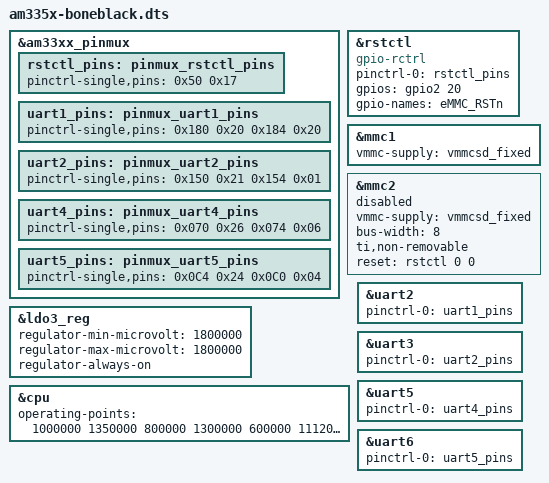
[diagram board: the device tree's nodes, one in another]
/*
 * Copyright (C) 2012 Texas Instruments Incorporated - http://www.ti.com/
 *
 * This program is free software; you can redistribute it and/or modify
 * it under the terms of the GNU General Public License version 2 as
 * published by the Free Software Foundation.
 */
/dts-v1/;

/include/ "am33xx.dtsi"

/include/ "am335x-bone-common.dtsi"

&am33xx_pinmux {
	rstctl_pins: pinmux_rstctl_pins {
		pinctrl-single,pins = <
			/* eMMC_RSTn */
			0x50 0x17	/* gpmc_a4.gpio1_20, OUTPUT | MODE7 | PULLUP */
		>;
	};

	uart1_pins: pinmux_uart1_pins {
		pinctrl-single,pins = <
			0x180 0x20	/* uart1_rxd.uart1_rxd */
			0x184 0x20	/* uart1_txd.uart1_txd */
		>;
	};

	uart2_pins: pinmux_uart2_pins {
		pinctrl-single,pins = <
			0x150 0x21	/* spi0_sclk.uart2_rxd | MODE1 */
			0x154 0x01	/* spi0_d0.uart2_txd | MODE1 */
		>;
	};

	uart4_pins: pinmux_uart4_pins {
		pinctrl-single,pins = <
			0x070 0x26	/* gpmc_wait0.uart4_rxd | MODE6 */
			0x074 0x06	/* gpmc_wpn.uart4_txd | MODE6 */
		>;
	};

	uart5_pins: pinmux_uart5_pins {
		pinctrl-single,pins = <
			0x0C4 0x24	/* lcd_data9.uart5_rxd | MODE4 */
			0x0C0 0x04	/* lcd_data8.uart5_txd | MODE4 */
		>;
	};
};

&ldo3_reg {
	regulator-min-microvolt = <1800000>;
	regulator-max-microvolt = <1800000>;
	regulator-always-on;
};

&rstctl {
	status = "okay";
	compatible = "gpio-rctrl";
	pinctrl-names = "default";
	pinctrl-0 = <&rstctl_pins>;

	#reset-cells = <2>;

	gpios = <&gpio2 20 0x00>;
	gpio-names = "eMMC_RSTn";
};

&mmc1 {
	vmmc-supply = <&vmmcsd_fixed>;
};

&mmc2 {
	vmmc-supply = <&vmmcsd_fixed>;
	bus-width = <8>;
	ti,non-removable;
	status = "disabled";

	reset = <&rstctl 0 0>;
	reset-names = "eMMC_RSTn-CONSUMER";
};


&cpu {
	/*
	 * To consider voltage drop between PMIC and SoC,
	 * tolerance value is reduced to 2% from 4% and
	 * voltage value is increased as a precaution.
	 */
	operating-points = <
		/* kHz    uV */
		1000000	1350000
		800000	1300000
		600000  1112000
		300000   969000
	>;
};

&uart2 {
	pinctrl-names = "default";
	pinctrl-0 = <&uart1_pins>;

	status = "okay";
};

&uart3 {
	pinctrl-names = "default";
	pinctrl-0 = <&uart2_pins>;

	status = "okay";
};

&uart5 {
	pinctrl-names = "default";
	pinctrl-0 = <&uart4_pins>;

	status = "okay";
};

&uart6 {
	pinctrl-names = "default";
	pinctrl-0 = <&uart5_pins>;

	status = "okay";
};
